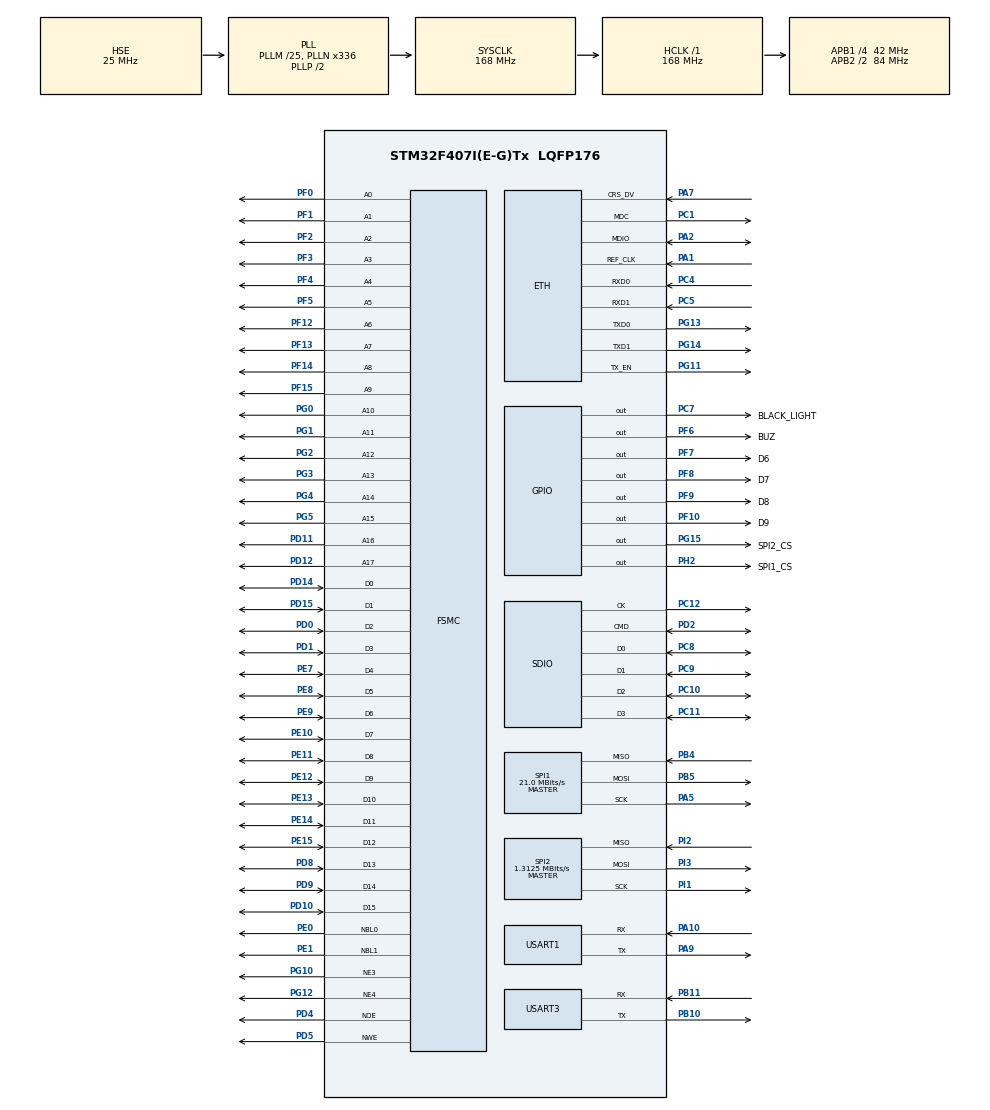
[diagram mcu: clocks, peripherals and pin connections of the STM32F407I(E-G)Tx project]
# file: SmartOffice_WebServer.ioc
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Dma.Request0=SDIO_RX
Dma.Request1=SDIO_TX
Dma.SDIO_RX.0.Direction=DMA_PERIPH_TO_MEMORY
Dma.SDIO_RX.0.FIFOMode=DMA_FIFOMODE_ENABLE
Dma.SDIO_RX.0.FIFOThreshold=DMA_FIFO_THRESHOLD_FULL
Dma.SDIO_RX.0.Instance=DMA2_Stream3
Dma.SDIO_RX.0.MemBurst=DMA_MBURST_INC4
Dma.SDIO_RX.0.MemDataAlignment=DMA_MDATAALIGN_WORD
Dma.SDIO_RX.0.MemInc=DMA_MINC_ENABLE
Dma.SDIO_RX.0.Mode=DMA_PFCTRL
Dma.SDIO_RX.0.PeriphBurst=DMA_PBURST_INC4
Dma.SDIO_RX.0.PeriphDataAlignment=DMA_PDATAALIGN_WORD
Dma.SDIO_RX.0.PeriphInc=DMA_PINC_DISABLE
Dma.SDIO_RX.0.Priority=DMA_PRIORITY_HIGH
Dma.SDIO_TX.1.Direction=DMA_MEMORY_TO_PERIPH
Dma.SDIO_TX.1.FIFOMode=DMA_FIFOMODE_ENABLE
Dma.SDIO_TX.1.FIFOThreshold=DMA_FIFO_THRESHOLD_FULL
Dma.SDIO_TX.1.Instance=DMA2_Stream6
Dma.SDIO_TX.1.MemBurst=DMA_MBURST_INC4
Dma.SDIO_TX.1.MemDataAlignment=DMA_MDATAALIGN_WORD
Dma.SDIO_TX.1.MemInc=DMA_MINC_ENABLE
Dma.SDIO_TX.1.Mode=DMA_PFCTRL
Dma.SDIO_TX.1.PeriphBurst=DMA_PBURST_INC4
Dma.SDIO_TX.1.PeriphDataAlignment=DMA_PDATAALIGN_WORD
Dma.SDIO_TX.1.PeriphInc=DMA_PINC_DISABLE
Dma.SDIO_TX.1.Priority=DMA_PRIORITY_HIGH
ETH.MediaInterface=ETH_MEDIA_INTERFACE_RMII
ETH.PHY_BSR=0x01
ETH.PHY_DUPLEX_STATUS=0x0004
ETH.PHY_Name_RMII=DP83848_PHY_ADDRESS
ETH.PHY_SPEED_STATUS=0x0002
ETH.PHY_SR=0x10
ETH.RxMode=ETH_RXINTERRUPT_MODE
FATFS._CODE_PAGE=936
FATFS._USE_LFN=3
FREERTOS.Tasks01=TouchTask,1,1024,Touch_Task,Default,NULL,Dynamic,NULL,NULL;GuiTask,-1,2048,Gui_Task,Default,NULL,Dynamic,NULL,NULL;WebServer,2,4096,Web_Server,Default,NULL,Dynamic,NULL,NULL;ZigbeeTask,0,128,Zigbee_Task,Default,NULL,Dynamic,NULL,NULL
FREERTOS.configTOTAL_HEAP_SIZE=40960
FSMC.AddressSetupTime1=1
FSMC.AddressSetupTime2=1
FSMC.DataSetupTime1=3
FSMC.DataSetupTime2=3
FSMC.WriteOperation1=FSMC_WRITE_OPERATION_ENABLE
LWIP.GATEWAY_ADDRESS=192.168.001.001
LWIP.IP_ADDRESS=192.168.001.007
LWIP.LWIP_DHCP=0
LWIP.LWIP_NETIF_LINK_CALLBACK=1
LWIP.MEM_SIZE=10240
LWIP.NETMASK_ADDRESS=255.255.255.000
LWIP.Version=v2.0.3_Cube
Mcu.Family=STM32F4
Mcu.Name=STM32F407I(E-G)Tx
Mcu.Package=LQFP176
NVIC.DMA2_Stream3_IRQn=true\:6\:0\:true\:false\:true\:true\:false\:true
NVIC.DMA2_Stream6_IRQn=true\:6\:0\:true\:false\:true\:true\:false\:true
NVIC.ETH_IRQn=true\:5\:0\:false\:false\:true\:true\:false\:true
NVIC.PriorityGroup=NVIC_PRIORITYGROUP_4
NVIC.SDIO_IRQn=true\:5\:0\:false\:false\:true\:true\:true\:true
NVIC.TIM1_UP_TIM10_IRQn=true\:0\:0\:false\:false\:true\:false\:false\:true
NVIC.TimeBase=TIM1_UP_TIM10_IRQn
NVIC.TimeBaseIP=TIM1
NVIC.USART1_IRQn=true\:5\:0\:false\:false\:true\:true\:true\:true
PA1.Mode=RMII
PA1.Signal=ETH_REF_CLK
PA10.Mode=Asynchronous
PA10.Signal=USART1_RX
PA13.Mode=Serial_Wire
PA13.Signal=SYS_JTMS-SWDIO
PA14.Mode=Serial_Wire
PA14.Signal=SYS_JTCK-SWCLK
PA2.Mode=RMII
PA2.Signal=ETH_MDIO
PA5.Mode=Full_Duplex_Master
PA5.Signal=SPI1_SCK
PA7.Mode=RMII
PA7.Signal=ETH_CRS_DV
PA9.Mode=Asynchronous
PA9.Signal=USART1_TX
PB10.Mode=Asynchronous
PB10.Signal=USART3_TX
PB11.Mode=Asynchronous
PB11.Signal=USART3_RX
PB4.Mode=Full_Duplex_Master
PB4.Signal=SPI1_MISO
PB5.Mode=Full_Duplex_Master
PB5.Signal=SPI1_MOSI
PC1.Mode=RMII
PC1.Signal=ETH_MDC
PC10.Mode=SD_4_bits_Wide_bus
PC10.Signal=SDIO_D2
PC11.Mode=SD_4_bits_Wide_bus
PC11.Signal=SDIO_D3
PC12.Mode=SD_4_bits_Wide_bus
PC12.Signal=SDIO_CK
PC4.Mode=RMII
PC4.Signal=ETH_RXD0
PC5.Mode=RMII
PC5.Signal=ETH_RXD1
PC7.GPIO_Label=BLACK_LIGHT
PC7.PinState=GPIO_PIN_SET
PC7.Signal=GPIO_Output
PC8.Mode=SD_4_bits_Wide_bus
PC8.Signal=SDIO_D0
PC9.Mode=SD_4_bits_Wide_bus
PC9.Signal=SDIO_D1
PD0.Signal=FSMC_D2_DA2
PD1.Signal=FSMC_D3_DA3
PD10.Signal=FSMC_D15_DA15
PD11.Signal=FSMC_A16_CLE
PD12.Signal=FSMC_A17_ALE
PD14.Signal=FSMC_D0_DA0
PD15.Signal=FSMC_D1_DA1
PD2.Mode=SD_4_bits_Wide_bus
PD2.Signal=SDIO_CMD
PD4.Signal=FSMC_NOE
PD5.Signal=FSMC_NWE
PD8.Signal=FSMC_D13_DA13
PD9.Signal=FSMC_D14_DA14
PE0.Signal=FSMC_NBL0
PE1.Signal=FSMC_NBL1
PE10.Signal=FSMC_D7_DA7
PE11.Signal=FSMC_D8_DA8
PE12.Signal=FSMC_D9_DA9
PE13.Signal=FSMC_D10_DA10
PE14.Signal=FSMC_D11_DA11
PE15.Signal=FSMC_D12_DA12
PE7.Signal=FSMC_D4_DA4
PE8.Signal=FSMC_D5_DA5
PE9.Signal=FSMC_D6_DA6
PF0.Signal=FSMC_A0
PF1.Signal=FSMC_A1
PF10.GPIO_Label=D9
PF10.PinState=GPIO_PIN_SET
PF10.Signal=GPIO_Output
PF12.Signal=FSMC_A6
PF13.Signal=FSMC_A7
PF14.Signal=FSMC_A8
PF15.Signal=FSMC_A9
PF2.Signal=FSMC_A2
PF3.Signal=FSMC_A3
PF4.Signal=FSMC_A4
PF5.Signal=FSMC_A5
PF6.GPIO_Label=BUZ
PF6.Signal=GPIO_Output
PF7.GPIO_Label=D6
PF7.PinState=GPIO_PIN_SET
PF7.Signal=GPIO_Output
PF8.GPIO_Label=D7
PF8.PinState=GPIO_PIN_SET
PF8.Signal=GPIO_Output
PF9.GPIO_Label=D8
PF9.PinState=GPIO_PIN_SET
PF9.Signal=GPIO_Output
PG0.Signal=FSMC_A10
PG1.Signal=FSMC_A11
PG10.Mode=NorPsramChipSelect3_1
PG10.Signal=FSMC_NE3
PG11.Mode=RMII
PG11.Signal=ETH_TX_EN
PG12.Mode=NorPsramChipSelect4_2
PG12.Signal=FSMC_NE4
PG13.Mode=RMII
PG13.Signal=ETH_TXD0
PG14.Mode=RMII
PG14.Signal=ETH_TXD1
PG15.GPIO_Label=SPI2_CS
PG15.PinState=GPIO_PIN_SET
PG15.Signal=GPIO_Output
PG2.Signal=FSMC_A12
PG3.Signal=FSMC_A13
PG4.Signal=FSMC_A14
PG5.Signal=FSMC_A15
PH0-OSC_IN.Mode=HSE-External-Oscillator
PH0-OSC_IN.Signal=RCC_OSC_IN
PH1-OSC_OUT.Mode=HSE-External-Oscillator
PH1-OSC_OUT.Signal=RCC_OSC_OUT
PH2.GPIO_Label=SPI1_CS
PH2.PinState=GPIO_PIN_SET
PH2.Signal=GPIO_Output
PI1.Mode=Full_Duplex_Master
PI1.Signal=SPI2_SCK
PI2.Mode=Full_Duplex_Master
PI2.Signal=SPI2_MISO
PI3.Mode=Full_Duplex_Master
PI3.Signal=SPI2_MOSI
ProjectManager.HeapSize=0x1000
ProjectManager.StackSize=0x400
ProjectManager.TargetToolchain=MDK-ARM V5
RCC.48MHZClocksFreq_Value=42000000
RCC.AHBFreq_Value=168000000
RCC.APB1CLKDivider=RCC_HCLK_DIV4
RCC.APB1Freq_Value=42000000
RCC.APB1TimFreq_Value=84000000
RCC.APB2CLKDivider=RCC_HCLK_DIV2
RCC.APB2Freq_Value=84000000
RCC.APB2TimFreq_Value=168000000
RCC.CortexFreq_Value=168000000
RCC.HCLKFreq_Value=168000000
RCC.HSE_VALUE=25000000
RCC.HSI_VALUE=16000000
RCC.LSE_VALUE=32768
RCC.PLLM=25
RCC.PLLN=336
RCC.PLLQ=8
RCC.PLLSourceVirtual=RCC_PLLSOURCE_HSE
RCC.SYSCLKFreq_VALUE=168000000
RCC.SYSCLKSource=RCC_SYSCLKSOURCE_PLLCLK
RCC.VCOOutputFreq_Value=336000000
SH.FSMC_A0.0=FSMC_A0,18b-a1
SH.FSMC_A0.1=FSMC_A0,A0_2
SH.FSMC_A1.0=FSMC_A1,18b-a1
SH.FSMC_A10.0=FSMC_A10,18b-a1
SH.FSMC_A11.0=FSMC_A11,18b-a1
SH.FSMC_A12.0=FSMC_A12,18b-a1
SH.FSMC_A13.0=FSMC_A13,18b-a1
SH.FSMC_A14.0=FSMC_A14,18b-a1
SH.FSMC_A15.0=FSMC_A15,18b-a1
SH.FSMC_A16_CLE.0=FSMC_A16,18b-a1
SH.FSMC_A17_ALE.0=FSMC_A17,18b-a1
SH.FSMC_A2.0=FSMC_A2,18b-a1
SH.FSMC_A3.0=FSMC_A3,18b-a1
SH.FSMC_A4.0=FSMC_A4,18b-a1
SH.FSMC_A5.0=FSMC_A5,18b-a1
SH.FSMC_A6.0=FSMC_A6,18b-a1
SH.FSMC_A7.0=FSMC_A7,18b-a1
SH.FSMC_A8.0=FSMC_A8,18b-a1
SH.FSMC_A9.0=FSMC_A9,18b-a1
SH.FSMC_D0_DA0.0=FSMC_D0,16b-d1
SH.FSMC_D0_DA0.1=FSMC_D0,16b-d2
SH.FSMC_D10_DA10.0=FSMC_D10,16b-d1
SH.FSMC_D10_DA10.1=FSMC_D10,16b-d2
SH.FSMC_D11_DA11.0=FSMC_D11,16b-d1
SH.FSMC_D11_DA11.1=FSMC_D11,16b-d2
SH.FSMC_D12_DA12.0=FSMC_D12,16b-d1
SH.FSMC_D12_DA12.1=FSMC_D12,16b-d2
SH.FSMC_D13_DA13.0=FSMC_D13,16b-d1
SH.FSMC_D13_DA13.1=FSMC_D13,16b-d2
SH.FSMC_D14_DA14.0=FSMC_D14,16b-d1
SH.FSMC_D14_DA14.1=FSMC_D14,16b-d2
SH.FSMC_D15_DA15.0=FSMC_D15,16b-d1
SH.FSMC_D15_DA15.1=FSMC_D15,16b-d2
SH.FSMC_D1_DA1.0=FSMC_D1,16b-d1
SH.FSMC_D1_DA1.1=FSMC_D1,16b-d2
SH.FSMC_D2_DA2.0=FSMC_D2,16b-d1
SH.FSMC_D2_DA2.1=FSMC_D2,16b-d2
SH.FSMC_D3_DA3.0=FSMC_D3,16b-d1
SH.FSMC_D3_DA3.1=FSMC_D3,16b-d2
SH.FSMC_D4_DA4.0=FSMC_D4,16b-d1
SH.FSMC_D4_DA4.1=FSMC_D4,16b-d2
SH.FSMC_D5_DA5.0=FSMC_D5,16b-d1
SH.FSMC_D5_DA5.1=FSMC_D5,16b-d2
SH.FSMC_D6_DA6.0=FSMC_D6,16b-d1
SH.FSMC_D6_DA6.1=FSMC_D6,16b-d2
SH.FSMC_D7_DA7.0=FSMC_D7,16b-d1
SH.FSMC_D7_DA7.1=FSMC_D7,16b-d2
SH.FSMC_D8_DA8.0=FSMC_D8,16b-d1
SH.FSMC_D8_DA8.1=FSMC_D8,16b-d2
SH.FSMC_D9_DA9.0=FSMC_D9,16b-d1
SH.FSMC_D9_DA9.1=FSMC_D9,16b-d2
SH.FSMC_NBL0.0=FSMC_NBL0,2ByteEnable1
SH.FSMC_NBL1.0=FSMC_NBL1,2ByteEnable1
SH.FSMC_NOE.0=FSMC_NOE,Sram1
SH.FSMC_NOE.1=FSMC_NOE,Lcd2
SH.FSMC_NWE.0=FSMC_NWE,Sram1
SH.FSMC_NWE.1=FSMC_NWE,Lcd2
SPI1.BaudRatePrescaler=SPI_BAUDRATEPRESCALER_4
SPI1.CalculateBaudRate=21.0 MBits/s
SPI1.Direction=SPI_DIRECTION_2LINES
SPI1.Mode=SPI_MODE_MASTER
SPI1.VirtualType=VM_MASTER
SPI2.BaudRatePrescaler=SPI_BAUDRATEPRESCALER_32
SPI2.CalculateBaudRate=1.3125 MBits/s
SPI2.Direction=SPI_DIRECTION_2LINES
SPI2.Mode=SPI_MODE_MASTER
SPI2.VirtualType=VM_MASTER
USART1.VirtualMode=VM_ASYNC
USART3.VirtualMode=VM_ASYNC
VP_CRC_VS_CRC.Mode=CRC_Activate
VP_FATFS_VS_SDIO.Mode=SDIO
VP_FREERTOS_VS_CMSIS_V1.Mode=CMSIS_V1
VP_LWIP_VS_Enabled.Mode=Enabled
VP_SYS_VS_tim1.Mode=TIM1
board=custom

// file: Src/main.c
/* USER CODE BEGIN Header */
/**
  ******************************************************************************
  * @file           : main.c
  * @brief          : Main program body
  ******************************************************************************
  * @attention
  *
  * <h2><center>&copy; Copyright (c) 2020 STMicroelectronics.
  * All rights reserved.</center></h2>
  *
  * This software component is licensed by ST under Ultimate Liberty license
  * SLA0044, the "License"; You may not use this file except in compliance with
  * the License. You may obtain a copy of the License at:
  *                             www.st.com/SLA0044
  *
  ******************************************************************************
  */
/* USER CODE END Header */

#include "main.h"
#include "cmsis_os.h"
#include "crc.h"
#include "dma.h"
#include "fatfs.h"
#include "lwip.h"
#include "sdio.h"
#include "spi.h"
#include "usart.h"
#include "gpio.h"
#include "fsmc.h"

/* USER CODE BEGIN Includes */

#include "stdio.h"
/* USER CODE END Includes */

void SystemClock_Config(void);
void MX_FREERTOS_Init(void);

int main(void)
{

  /* MCU Configuration--------------------------------------------------------*/

  /* Reset of all peripherals, Initializes the Flash interface and the Systick. */
  HAL_Init();

  /* Configure the system clock */
  SystemClock_Config();

  /* Initialize all configured peripherals */
  MX_GPIO_Init();
  MX_DMA_Init();
  MX_USART1_UART_Init();
  MX_USART3_UART_Init();
  MX_FSMC_Init();
  MX_SDIO_SD_Init();
  MX_SPI1_Init();
  MX_SPI2_Init();
  MX_CRC_Init();

  /* Call init function for freertos objects (in freertos.c) */
  MX_FREERTOS_Init();

  /* Start scheduler */
  osKernelStart();

  /* We should never get here as control is now taken by the scheduler */

  /* Infinite loop */
  while (1)
  {

  }
}

void SystemClock_Config(void)
{
  RCC_OscInitTypeDef RCC_OscInitStruct = {0};
  RCC_ClkInitTypeDef RCC_ClkInitStruct = {0};

  /** Configure the main internal regulator output voltage
  */
  __HAL_RCC_PWR_CLK_ENABLE();
  __HAL_PWR_VOLTAGESCALING_CONFIG(PWR_REGULATOR_VOLTAGE_SCALE1);
  /** Initializes the CPU, AHB and APB busses clocks
  */
  RCC_OscInitStruct.OscillatorType = RCC_OSCILLATORTYPE_HSE;
  RCC_OscInitStruct.HSEState = RCC_HSE_ON;
  RCC_OscInitStruct.PLL.PLLState = RCC_PLL_ON;
  RCC_OscInitStruct.PLL.PLLSource = RCC_PLLSOURCE_HSE;
  RCC_OscInitStruct.PLL.PLLM = 25;
  RCC_OscInitStruct.PLL.PLLN = 336;
  RCC_OscInitStruct.PLL.PLLP = RCC_PLLP_DIV2;
  RCC_OscInitStruct.PLL.PLLQ = 8;
  if (HAL_RCC_OscConfig(&RCC_OscInitStruct) != HAL_OK)
  {
    Error_Handler();
  }
  /** Initializes the CPU, AHB and APB busses clocks
  */
  RCC_ClkInitStruct.ClockType = RCC_CLOCKTYPE_HCLK|RCC_CLOCKTYPE_SYSCLK
                              |RCC_CLOCKTYPE_PCLK1|RCC_CLOCKTYPE_PCLK2;
  RCC_ClkInitStruct.SYSCLKSource = RCC_SYSCLKSOURCE_PLLCLK;
  RCC_ClkInitStruct.AHBCLKDivider = RCC_SYSCLK_DIV1;
  RCC_ClkInitStruct.APB1CLKDivider = RCC_HCLK_DIV4;
  RCC_ClkInitStruct.APB2CLKDivider = RCC_HCLK_DIV2;

  if (HAL_RCC_ClockConfig(&RCC_ClkInitStruct, FLASH_LATENCY_5) != HAL_OK)
  {
    Error_Handler();
  }
}

/* USER CODE BEGIN 4 */

int fputc(int ch, FILE *f)
{
    while((USART3->SR & 0X40)==0);
    USART3->DR = (uint8_t) ch;
    return ch;
}

/* USER CODE END 4 */

void HAL_TIM_PeriodElapsedCallback(TIM_HandleTypeDef *htim)
{
  if (htim->Instance == TIM1) {
    HAL_IncTick();
  }
}

void Error_Handler(void)
{
}

/************************ (C) COPYRIGHT STMicroelectronics *****END OF FILE****/

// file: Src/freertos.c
/* USER CODE BEGIN Header */
/**
  ******************************************************************************
  * File Name          : freertos.c
  * Description        : Code for freertos applications
  ******************************************************************************
  * @attention
  *
  * <h2><center>&copy; Copyright (c) 2020 STMicroelectronics.
  * All rights reserved.</center></h2>
  *
  * This software component is licensed by ST under Ultimate Liberty license
  * SLA0044, the "License"; You may not use this file except in compliance with
  * the License. You may obtain a copy of the License at:
  *                             www.st.com/SLA0044
  *
  ******************************************************************************
  */
/* USER CODE END Header */

#include "FreeRTOS.h"
#include "task.h"
#include "main.h"
#include "cmsis_os.h"

/* USER CODE BEGIN Includes */
#include "stdio.h"
#include "GUI.h"
#include "httpserver-socket.h" //包含webserver头文件
#include "string.h"
#include "protocol.h"
/* USER CODE END Includes */

/* USER CODE BEGIN Variables */

uint8_t ZigbeeBuff[40];
osMessageQId ZigbeeQueueHandle;

/* USER CODE END Variables */
osThreadId TouchTaskHandle;
osThreadId GuiTaskHandle;
osThreadId WebServerHandle;
osThreadId ZigbeeTaskHandle;

/* USER CODE BEGIN FunctionPrototypes */

extern void MainTask(void);

/* USER CODE END FunctionPrototypes */

void Touch_Task(void const * argument);
void Gui_Task(void const * argument);
void Web_Server(void const * argument);
void Zigbee_Task(void const * argument);

extern void MX_FATFS_Init(void);
extern void MX_LWIP_Init(void);
void MX_FREERTOS_Init(void); /* (MISRA C 2004 rule 8.1) */

/* GetIdleTaskMemory prototype (linked to static allocation support) */
void vApplicationGetIdleTaskMemory( StaticTask_t **ppxIdleTaskTCBBuffer, StackType_t **ppxIdleTaskStackBuffer, uint32_t *pulIdleTaskStackSize );

/* USER CODE BEGIN GET_IDLE_TASK_MEMORY */
static StaticTask_t xIdleTaskTCBBuffer;
static StackType_t xIdleStack[configMINIMAL_STACK_SIZE];

void vApplicationGetIdleTaskMemory( StaticTask_t **ppxIdleTaskTCBBuffer, StackType_t **ppxIdleTaskStackBuffer, uint32_t *pulIdleTaskStackSize )
{
  *ppxIdleTaskTCBBuffer = &xIdleTaskTCBBuffer;
  *ppxIdleTaskStackBuffer = &xIdleStack[0];
  *pulIdleTaskStackSize = configMINIMAL_STACK_SIZE;
  /* place for user code */
}
/* USER CODE END GET_IDLE_TASK_MEMORY */

void MX_FREERTOS_Init(void) {

  /* USER CODE BEGIN RTOS_QUEUES */
	osMessageQDef(ZigbeeQueue, 40, uint8_t);
  ZigbeeQueueHandle = osMessageCreate(osMessageQ(ZigbeeQueue), NULL);
  /* add queues, ... */
  /* USER CODE END RTOS_QUEUES */

  /* Create the thread(s) */
  /* definition and creation of TouchTask */
  osThreadDef(TouchTask, Touch_Task, osPriorityAboveNormal, 0, 1024);
  TouchTaskHandle = osThreadCreate(osThread(TouchTask), NULL);

  /* definition and creation of GuiTask */
  osThreadDef(GuiTask, Gui_Task, osPriorityBelowNormal, 0, 2048);
  GuiTaskHandle = osThreadCreate(osThread(GuiTask), NULL);

  /* definition and creation of WebServer */
	//websever任务分配的栈空间由4096变成2048 = 8KB
	//原因 我在读取网页文件时，需要动态分配内存空间，不够用了，在这边提取一点
  osThreadDef(WebServer, Web_Server, osPriorityHigh, 0, 2048);
  WebServerHandle = osThreadCreate(osThread(WebServer), NULL);

  /* definition and creation of ZigbeeTask */
  osThreadDef(ZigbeeTask, Zigbee_Task, osPriorityNormal, 0, 128);
  ZigbeeTaskHandle = osThreadCreate(osThread(ZigbeeTask), NULL);

}

void Touch_Task(void const * argument)
{

  //原有的Fatfs和lwip初始化工作移植到webserver中

  /* USER CODE BEGIN Touch_Task */
	printf("system is runing!\r\n");
  /* Infinite loop */
  for(;;)
  {
		//ִ触摸屏需要轮询检测，不然emWin没有办法触发事件
		GUI_TOUCH_Exec();
		osDelay(20);
  }
  /* USER CODE END Touch_Task */
}

void Gui_Task(void const * argument)
{
  /* USER CODE BEGIN Gui_Task */

  /* Infinite loop */
	MainTask();
  /* USER CODE END Gui_Task */
}

void Web_Server(void const * argument)
{
  /* USER CODE BEGIN Web_Server */
	//webserver中用到了socket和fatfs，在webserver任务运行前，需要完成前两项内容初始化工作
  /* init code for FATFS */
  MX_FATFS_Init();

  /* init code for LWIP */
  MX_LWIP_Init();
  /* Infinite loop */
  for(;;)
  {
		//Webserver主线程任务
    http_server_socket_thread(NULL);
  }
  /* USER CODE END Web_Server */
}

void Zigbee_Task(void const * argument)
{
  /* USER CODE BEGIN Zigbee_Task */
	uint8_t u8Index;
  /* Infinite loop */
  for(;;)
  {
	  //每次读取消息之前，把索引初始化为0
	  u8Index = 0;
	  //1、一直等待接收消息,第一个消息应该放在消息缓冲区的第一个元素上
		if(xQueueReceive(ZigbeeQueueHandle,&ZigbeeBuff[u8Index++],portMAX_DELAY)==pdPASS){
			while(xQueueReceive(ZigbeeQueueHandle,&ZigbeeBuff[u8Index++],50)){}
			//完成解析以后，要清空接收缓冲区，不然会出现问题
			  ProtocolParse(ZigbeeBuff,u8Index-1);
		    memset(ZigbeeBuff,0,40);

		}
  }
  /* USER CODE END Zigbee_Task */
}

/************************ (C) COPYRIGHT STMicroelectronics *****END OF FILE****/
